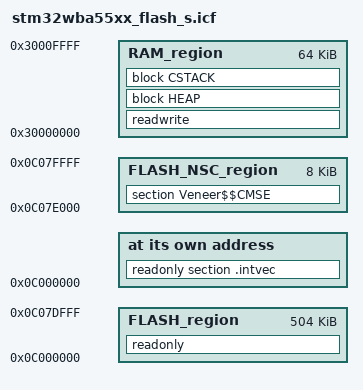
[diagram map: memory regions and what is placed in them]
/**********************************************************************************/
/**** Linker File (ICF)                                                        ****/
/**********************************************************************************/

/*-Symbols-*/

define symbol __region_FLASH_start__       = 0x0C000000;
define symbol __region_FLASH_end__         = 0x0C07DFFF;

define symbol __region_FLASH_NSC_start__   = 0x0C07E000;
define symbol __region_FLASH_NSC_end__     = 0x0C07FFFF;

define symbol __region_FLASH_NS_start__    = 0x08080000;
define symbol __region_FLASH_NS_end__      = 0x080FFFFF;

define symbol __region_RAM_start__         = 0x30000000;
define symbol __region_RAM_end__           = 0x3000FFFF;

define symbol __size_heap__                = 0x3000;
define symbol __size_cstack__              = 0x1000;

define symbol __intvec_start__             = __region_FLASH_start__;

/*-Memory Regions-*/
define memory mem with size = 4G;

define region FLASH_region     = mem:[from __region_FLASH_start__ to __region_FLASH_end__];
define region FLASH_NSC_region = mem:[from __region_FLASH_NSC_start__ to __region_FLASH_NSC_end__];
define region RAM_region       = mem:[from __region_RAM_start__ to __region_RAM_end__];

/*-Blocks-*/
define block HEAP      with alignment = 8, size = __size_heap__   { };
define block CSTACK    with alignment = 8, size = __size_cstack__ { };

/*-Initialization strategies-*/
initialize by copy { readwrite };
do not initialize  { section .noinit };

/*-Sections placements-*/
place at address mem:__intvec_start__ { readonly section .intvec };

place in FLASH_region       { readonly };
place in FLASH_NSC_region   { section Veneer$$CMSE };
place in RAM_region         { readwrite, block HEAP, block CSTACK };
